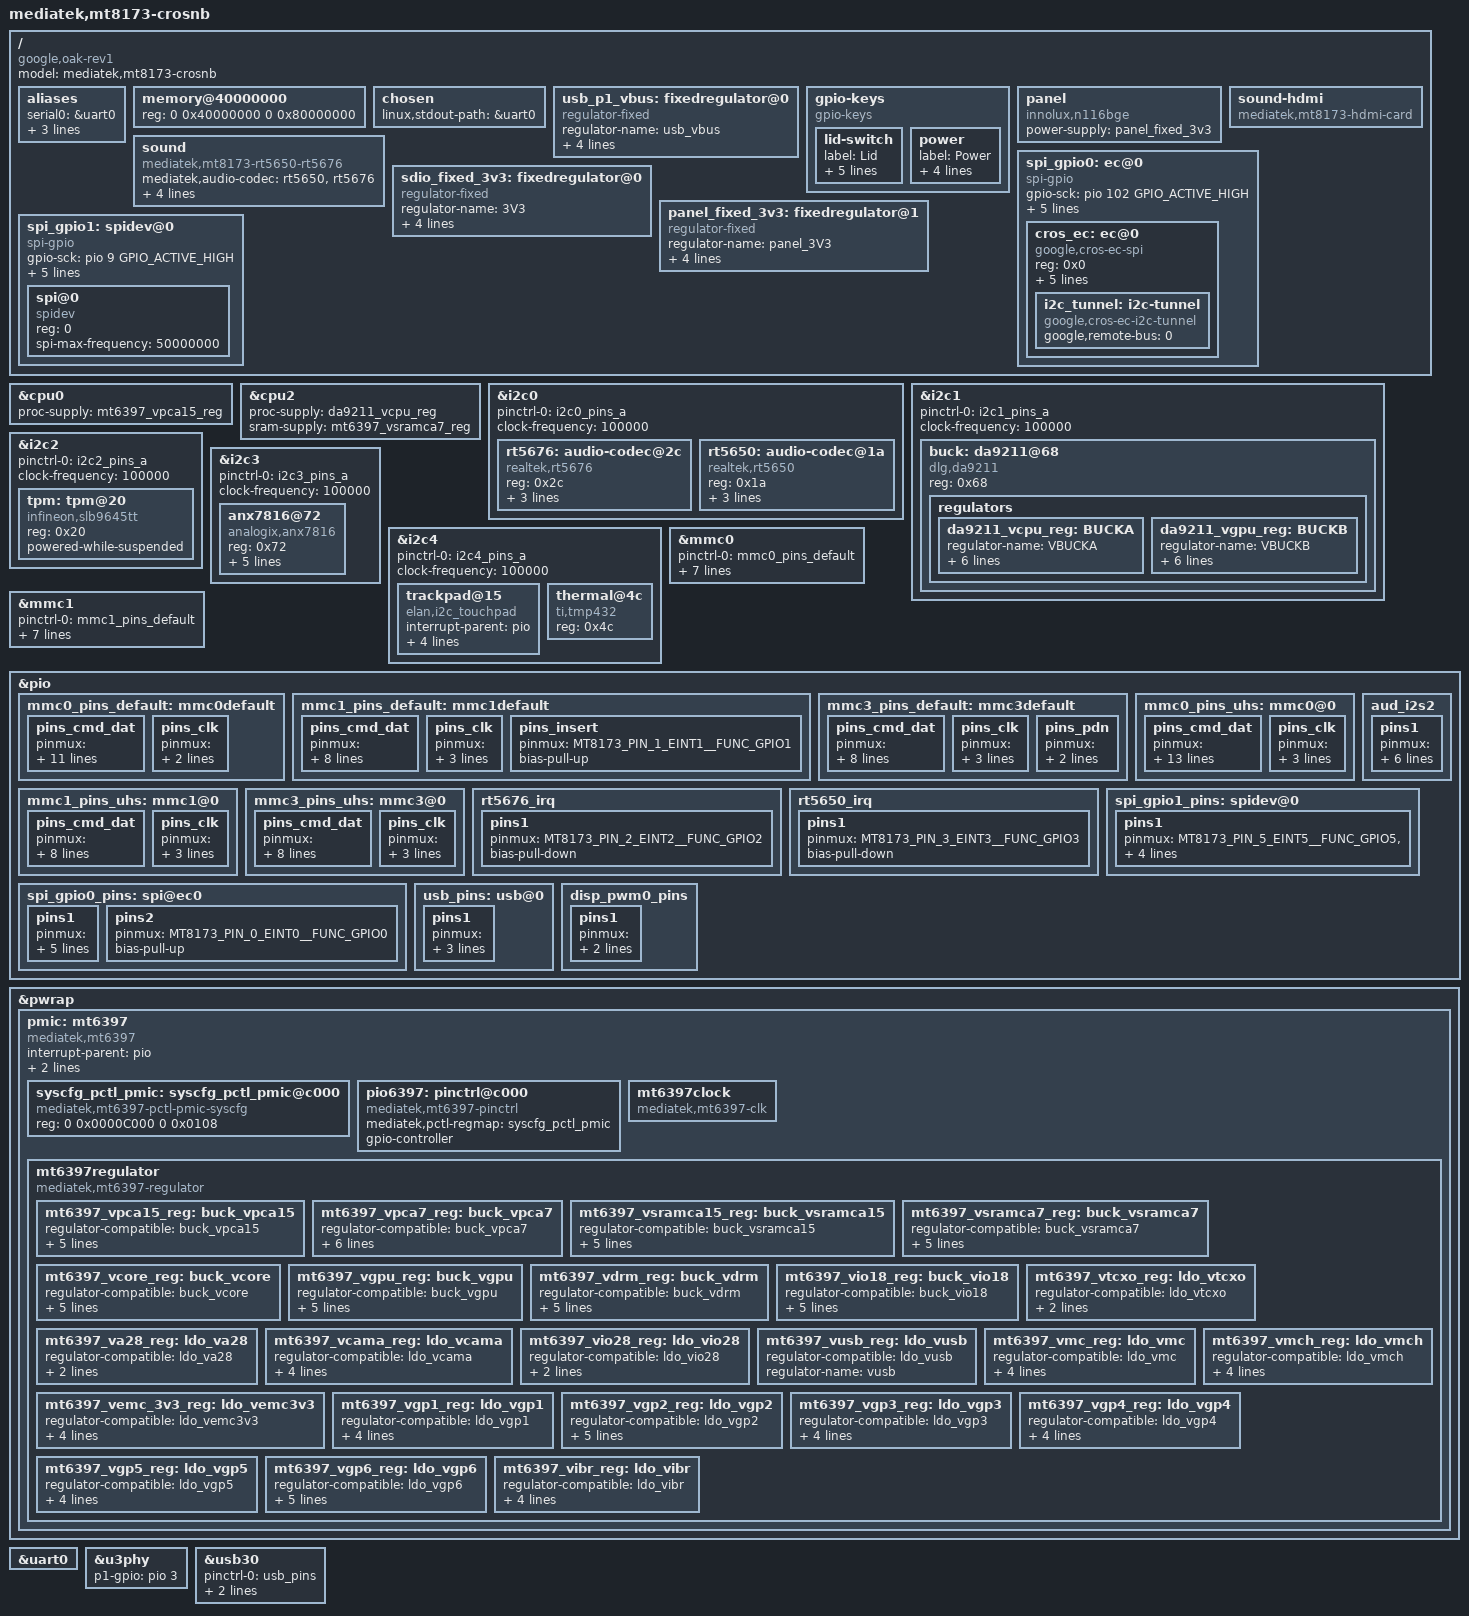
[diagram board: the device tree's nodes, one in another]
/*
 * Copyright (c) 2014 MediaTek Inc.
 * Author: Eddie Huang <eddie.huang@mediatek.com>
 *
 * This program is free software; you can redistribute it and/or modify
 * it under the terms of the GNU General Public License version 2 as
 * published by the Free Software Foundation.
 *
 * This program is distributed in the hope that it will be useful,
 * but WITHOUT ANY WARRANTY; without even the implied warranty of
 * MERCHANTABILITY or FITNESS FOR A PARTICULAR PURPOSE.  See the
 * GNU General Public License for more details.
 */

/dts-v1/;
#include <dt-bindings/input/input.h>
#include <dt-bindings/gpio/gpio.h>
#include "mt8173.dtsi"
#include "mt8173-pinfunc.h"

/ {
	model = "mediatek,mt8173-crosnb";
	compatible = "google,oak-rev1","google,oak","mediatek,mt8173";

	aliases {
		serial0 = &uart0;
		serial1 = &uart1;
		serial2 = &uart2;
		serial3 = &uart3;
	};

	memory@40000000 {
		device_type = "memory";
		reg = <0 0x40000000 0 0x80000000>;
	};

	chosen {
		linux,stdout-path = &uart0;
	};

	usb_p1_vbus: fixedregulator@0 {
		compatible = "regulator-fixed";
		regulator-name = "usb_vbus";
		regulator-min-microvolt = <5000000>;
		regulator-max-microvolt = <5000000>;
		gpio = <&pio 130 GPIO_ACTIVE_HIGH>;
		enable-active-high;
	};

	gpio-keys {
		compatible = "gpio-keys";
		lid-switch {
			label = "Lid";
			gpios = <&pio 12 GPIO_ACTIVE_LOW>;
			linux,input-type = <5>; /* EV_SW */
			linux,code = <0>; /* SW_LID */
			debounce-interval = <1>;
			gpio-key,wakeup;
		};
		power {
			label = "Power";
			gpios = <&pio 14 GPIO_ACTIVE_HIGH>;
			linux,code = <KEY_POWER>;
			debounce-interval = <1>;
			gpio-key,wakeup;
		};
	};

	panel: panel {
		compatible = "innolux,n116bge";
		power-supply =  <&panel_fixed_3v3>;
	};

	sound-hdmi {
		compatible = "mediatek,mt8173-hdmi-card";
	};

	sound {
		compatible = "mediatek,mt8173-rt5650-rt5676";
		mediatek,audio-codec = <&rt5650 &rt5676>;
		rt5650-clk-en-gpios = <&pio 16 GPIO_ACTIVE_HIGH>;
		rt5676-clk-en-gpios = <&pio 17 GPIO_ACTIVE_HIGH>;
		reg-vgp1-supply = <&mt6397_vgp1_reg>;
		pinctrl-names = "default";
		pinctrl-0 = <&aud_i2s2>;
		status = "okay";
	};

	spi_gpio0: ec@0 {
		compatible = "spi-gpio";
		#address-cells = <0x1>;
		#size-cells = <0>;
		gpio-sck = <&pio 102 GPIO_ACTIVE_HIGH>;
		gpio-miso = <&pio 103 GPIO_ACTIVE_HIGH>;
		gpio-mosi = <&pio 104 GPIO_ACTIVE_HIGH>;
		cs-gpios = <&pio 105 GPIO_ACTIVE_HIGH>;
		num-chipselects = <1>;
		pinctrl-names = "default";
		pinctrl-0 = <&spi_gpio0_pins>;
		status = "okay";
		/* clients */
		cros_ec: ec@0 {
			compatible = "google,cros-ec-spi";
			reg = <0x0>;
			spi-max-frequency = <18000000>;
			interrupt-parent = <&pio>;
			interrupts = <0 IRQ_TYPE_LEVEL_LOW>;
			google,cros-ec-spi-msg-delay = <500>;
			google,cros-ec-spi-pre-delay = <500>;

			i2c_tunnel: i2c-tunnel {
				compatible = "google,cros-ec-i2c-tunnel";
				google,remote-bus = <0>;
				#address-cells = <1>;
				#size-cells = <0>;
			};
		};
	};

	sdio_fixed_3v3: fixedregulator@0 {
		compatible = "regulator-fixed";
		regulator-name = "3V3";
		regulator-min-microvolt = <3300000>;
		regulator-max-microvolt = <3300000>;
		gpio = <&pio 100 0>;
		enable-active-high;
	};

	panel_fixed_3v3: fixedregulator@1 {
		compatible = "regulator-fixed";
		regulator-name = "panel_3V3";
		regulator-min-microvolt = <3300000>;
		regulator-max-microvolt = <3300000>;
		gpio = <&pio 41 0>;
		enable-active-high;
	};

	spi_gpio1: spidev@0 {
		compatible = "spi-gpio";
		#address-cells = <0x1>;
		#size-cells = <0>;

		gpio-sck = <&pio 9 GPIO_ACTIVE_HIGH>;
		gpio-miso = <&pio 5 GPIO_ACTIVE_HIGH>;
		gpio-mosi = <&pio 8 GPIO_ACTIVE_HIGH>;
		num-chipselects = <1>;
		cs-gpios = <&pio 6 GPIO_ACTIVE_LOW>;

		pinctrl-names = "default";
		pinctrl-0 = <&spi_gpio1_pins>;
		status = "okay";

		spi@0{
			compatible = "spidev";
			reg = <0>;
			spi-max-frequency = <50000000>;
		};
	};
};

&cpu0 {
	proc-supply = <&mt6397_vpca15_reg>;
};

&cpu2 {
	proc-supply = <&da9211_vcpu_reg>;
	sram-supply = <&mt6397_vsramca7_reg>;
};

&i2c0 {
	pinctrl-names = "default";
	pinctrl-0 = <&i2c0_pins_a>;
	status = "okay";
	clock-frequency = <100000>;
	#address-cells = <1>;
	#size-cells = <0>;
	rt5676: audio-codec@2c {
		compatible = "realtek,rt5676";
		reg = <0x2c>;
		interrupt-parent = <&pio>;
		interrupts = <2 IRQ_TYPE_EDGE_BOTH>;
		pinctrl-names = "default";
		pinctrl-0 = <&rt5676_irq>;
		status = "okay";
	};

	rt5650: audio-codec@1a {
		compatible = "realtek,rt5650";
		reg = <0x1a>;
		interrupt-parent = <&pio>;
		interrupts = <3 IRQ_TYPE_EDGE_BOTH>;
		pinctrl-names = "default";
		pinctrl-0 = <&rt5650_irq>;
		status = "okay";
	};
};

&i2c1 {
	pinctrl-names = "default";
	pinctrl-0 = <&i2c1_pins_a>;
	status = "okay";
	clock-frequency = <100000>;
	#address-cells = <1>;
	#size-cells = <0>;
	buck: da9211@68 {
		compatible = "dlg,da9211";
		reg = <0x68>;
		regulators {
			da9211_vcpu_reg: BUCKA {
				regulator-name = "VBUCKA";
				regulator-min-microvolt = < 700000>;
				regulator-max-microvolt = <1310000>;
				regulator-min-microamp	= <2000000>;
				regulator-max-microamp	= <4400000>;
				regulator-ramp-delay = <10000>;
				regulator-always-on;
			};
			da9211_vgpu_reg: BUCKB {
				regulator-name = "VBUCKB";
				regulator-min-microvolt = < 700000>;
				regulator-max-microvolt = <1310000>;
				regulator-min-microamp	= <2000000>;
				regulator-max-microamp	= <3000000>;
				regulator-ramp-delay = <10000>;
				regulator-always-on;
			};
		};
	};
};

&i2c2 {
	pinctrl-names = "default";
	pinctrl-0 = <&i2c2_pins_a>;
	status = "okay";
	clock-frequency = <100000>;
	#address-cells = <0x1>;
	#size-cells = <0>;
	tpm: tpm@20 {
		compatible = "infineon,slb9645tt";
		reg = <0x20>;
		powered-while-suspended;
	};
};

&i2c3 {
	pinctrl-names = "default";
	pinctrl-0 = <&i2c3_pins_a>;
	status = "okay";
	clock-frequency = <100000>;
	#address-cells = <0x1>;
	#size-cells = <0>;

	anx7816@72 {
		compatible = "analogix,anx7816";
		status = "ok";
		reg = <0x72>;
		analogix,p-dwn-gpio = <&pio 33 0x0>;
		analogix,reset-gpio = <&pio 98 0x0>;
		analogix,v10-ctrl-gpio = <&pio 35 0x0>;
		analogix,external-ldo-control = <1>;
		analogix,i2c-pull-up = <1>;
	};
};

&i2c4 {
	pinctrl-names = "default";
	pinctrl-0 = <&i2c4_pins_a>;
	status = "okay";
	clock-frequency = <100000>;
	#address-cells = <0x1>;
	#size-cells = <0>;
	trackpad@15 {
		compatible = "elan,i2c_touchpad";
		interrupt-parent = <&pio>;
		interrupts = <124 IRQ_TYPE_LEVEL_LOW>;
		reg = <0x15>;
		vcc-supply = <&mt6397_vgp6_reg>;
		wakeup-source;
	};
	thermal@4c {
		compatible = "ti,tmp432";
		reg = <0x4c>;
	};
};

&mmc0 {
	pinctrl-names = "default", "state_uhs";
	pinctrl-0 = <&mmc0_pins_default>;
	pinctrl-1 = <&mmc0_pins_uhs>;
	status = "okay";
	bus-width = <8>;
	max-frequency = <25000000>;
	cap-mmc-highspeed;
	vmmc-supply = <&mt6397_vemc_3v3_reg>;
	vqmmc-supply = <&mt6397_vio18_reg>;
	non-removable;
};

&mmc1 {
	pinctrl-names = "default", "state_uhs";
	pinctrl-0 = <&mmc1_pins_default>;
	pinctrl-1 = <&mmc1_pins_uhs>;
	status = "okay";
	bus-width = <8>;
	max-frequency = <25000000>;
	cap-sd-highspeed;
	sd-uhs-sdr25;
	vmmc-supply = <&mt6397_vmch_reg>;
	vqmmc-supply = <&mt6397_vmc_reg>;
};

&pio {
	mmc0_pins_default: mmc0default {
		pins_cmd_dat {
			pinmux = <MT8173_PIN_57_MSDC0_DAT0__FUNC_MSDC0_DAT0>,
				 <MT8173_PIN_58_MSDC0_DAT1__FUNC_MSDC0_DAT1>,
				 <MT8173_PIN_59_MSDC0_DAT2__FUNC_MSDC0_DAT2>,
				 <MT8173_PIN_60_MSDC0_DAT3__FUNC_MSDC0_DAT3>,
				 <MT8173_PIN_61_MSDC0_DAT4__FUNC_MSDC0_DAT4>,
				 <MT8173_PIN_62_MSDC0_DAT5__FUNC_MSDC0_DAT5>,
				 <MT8173_PIN_63_MSDC0_DAT6__FUNC_MSDC0_DAT6>,
				 <MT8173_PIN_64_MSDC0_DAT7__FUNC_MSDC0_DAT7>,
				 <MT8173_PIN_66_MSDC0_CMD__FUNC_MSDC0_CMD>,
				 <MT8173_PIN_68_MSDC0_RST___FUNC_MSDC0_RSTB>;
				bias-pull-up;
		};
		pins_clk {
			pinmux =  <MT8173_PIN_65_MSDC0_CLK__FUNC_MSDC0_CLK>;
				bias-pull-down;
		};
	};

	mmc1_pins_default: mmc1default {
		pins_cmd_dat {
			pinmux = <MT8173_PIN_73_MSDC1_DAT0__FUNC_MSDC1_DAT0>,
				 <MT8173_PIN_74_MSDC1_DAT1__FUNC_MSDC1_DAT1>,
				 <MT8173_PIN_75_MSDC1_DAT2__FUNC_MSDC1_DAT2>,
				 <MT8173_PIN_76_MSDC1_DAT3__FUNC_MSDC1_DAT3>,
				 <MT8173_PIN_78_MSDC1_CMD__FUNC_MSDC1_CMD>;
			input-enable;
			drive-strength = <MTK_DRIVE_4mA>;
			bias-pull-up = <MTK_PUPD_SET_R1R0_10>;
		};

		pins_clk {
			pinmux = <MT8173_PIN_77_MSDC1_CLK__FUNC_MSDC1_CLK>;
			bias-pull-down;
			drive-strength = <MTK_DRIVE_4mA>;
		};

		pins_insert {
			pinmux = <MT8173_PIN_1_EINT1__FUNC_GPIO1>;
			bias-pull-up;
		};
	};

	mmc3_pins_default: mmc3default {
		pins_cmd_dat {
			pinmux = <MT8173_PIN_22_MSDC3_DAT0__FUNC_MSDC3_DAT0>,
				 <MT8173_PIN_23_MSDC3_DAT1__FUNC_MSDC3_DAT1>,
				 <MT8173_PIN_24_MSDC3_DAT2__FUNC_MSDC3_DAT2>,
				 <MT8173_PIN_25_MSDC3_DAT3__FUNC_MSDC3_DAT3>,
				 <MT8173_PIN_27_MSDC3_CMD__FUNC_MSDC3_CMD>;
			input-enable;
			drive-strength = <MTK_DRIVE_4mA>;
			bias-pull-up = <MTK_PUPD_SET_R1R0_10>;
		};

		pins_clk {
			pinmux = <MT8173_PIN_26_MSDC3_CLK__FUNC_MSDC3_CLK>;
			bias-pull-down;
			drive-strength = <MTK_DRIVE_4mA>;
		};

		pins_pdn {
			pinmux = <MT8173_PIN_100_MSDC2_DAT0__FUNC_GPIO100>;
			output-high;
		};
	};

	mmc0_pins_uhs: mmc0@0{
		pins_cmd_dat {
			pinmux = <MT8173_PIN_57_MSDC0_DAT0__FUNC_MSDC0_DAT0>,
				 <MT8173_PIN_58_MSDC0_DAT1__FUNC_MSDC0_DAT1>,
				 <MT8173_PIN_59_MSDC0_DAT2__FUNC_MSDC0_DAT2>,
				 <MT8173_PIN_60_MSDC0_DAT3__FUNC_MSDC0_DAT3>,
				 <MT8173_PIN_61_MSDC0_DAT4__FUNC_MSDC0_DAT4>,
				 <MT8173_PIN_62_MSDC0_DAT5__FUNC_MSDC0_DAT5>,
				 <MT8173_PIN_63_MSDC0_DAT6__FUNC_MSDC0_DAT6>,
				 <MT8173_PIN_64_MSDC0_DAT7__FUNC_MSDC0_DAT7>,
				 <MT8173_PIN_68_MSDC0_RST___FUNC_MSDC0_RSTB>,
				 <MT8173_PIN_66_MSDC0_CMD__FUNC_MSDC0_CMD>;
			input-enable;
			drive-strength = <MTK_DRIVE_2mA>;
			bias-pull-up = <MTK_PUPD_SET_R1R0_01>;
		};

		pins_clk {
			pinmux = <MT8173_PIN_65_MSDC0_CLK__FUNC_MSDC0_CLK>;
			drive-strength = <MTK_DRIVE_2mA>;
			bias-pull-down = <MTK_PUPD_SET_R1R0_01>;
		};
	};

	mmc1_pins_uhs: mmc1@0 {
		pins_cmd_dat {
			pinmux = <MT8173_PIN_73_MSDC1_DAT0__FUNC_MSDC1_DAT0>,
				 <MT8173_PIN_74_MSDC1_DAT1__FUNC_MSDC1_DAT1>,
				 <MT8173_PIN_75_MSDC1_DAT2__FUNC_MSDC1_DAT2>,
				 <MT8173_PIN_76_MSDC1_DAT3__FUNC_MSDC1_DAT3>,
				 <MT8173_PIN_78_MSDC1_CMD__FUNC_MSDC1_CMD>;
			input-enable;
			drive-strength = <MTK_DRIVE_4mA>;
			bias-pull-up = <MTK_PUPD_SET_R1R0_10>;
		};

		pins_clk {
			pinmux = <MT8173_PIN_77_MSDC1_CLK__FUNC_MSDC1_CLK>;
			drive-strength = <MTK_DRIVE_4mA>;
			bias-pull-down = <MTK_PUPD_SET_R1R0_10>;
		};
	};

	mmc3_pins_uhs: mmc3@0 {
		pins_cmd_dat {
			pinmux = <MT8173_PIN_22_MSDC3_DAT0__FUNC_MSDC3_DAT0>,
				 <MT8173_PIN_23_MSDC3_DAT1__FUNC_MSDC3_DAT1>,
				 <MT8173_PIN_24_MSDC3_DAT2__FUNC_MSDC3_DAT2>,
				 <MT8173_PIN_25_MSDC3_DAT3__FUNC_MSDC3_DAT3>,
				 <MT8173_PIN_27_MSDC3_CMD__FUNC_MSDC3_CMD>;
			input-enable;
			drive-strength = <MTK_DRIVE_4mA>;
			bias-pull-up = <MTK_PUPD_SET_R1R0_10>;
		};

		pins_clk {
			pinmux = <MT8173_PIN_26_MSDC3_CLK__FUNC_MSDC3_CLK>;
			drive-strength = <MTK_DRIVE_4mA>;
			bias-pull-down = <MTK_PUPD_SET_R1R0_10>;
		};
	};

	aud_i2s2: aud_i2s2 {
		pins1 {
			pinmux = <MT8173_PIN_128_I2S0_LRCK__FUNC_I2S1_WS>,
					<MT8173_PIN_129_I2S0_BCK__FUNC_I2S1_BCK>,
					<MT8173_PIN_130_I2S0_MCK__FUNC_I2S1_MCK>,
					<MT8173_PIN_131_I2S0_DATA0__FUNC_I2S1_DO_1>,
					<MT8173_PIN_132_I2S0_DATA1__FUNC_I2S2_DI_2>;
			bias-pull-down;
		};
	};
	rt5676_irq: rt5676_irq {
		pins1 {
			pinmux = <MT8173_PIN_2_EINT2__FUNC_GPIO2>;
			bias-pull-down;
		};
	};

	rt5650_irq: rt5650_irq {
		pins1 {
			pinmux = <MT8173_PIN_3_EINT3__FUNC_GPIO3>;
			bias-pull-down;
		};
	};

	spi_gpio0_pins: spi@ec0 {
		pins1 {
			pinmux = <MT8173_PIN_102_MSDC2_DAT2__FUNC_GPIO102>,
				 <MT8173_PIN_103_MSDC2_DAT3__FUNC_GPIO103>,
				 <MT8173_PIN_104_MSDC2_CLK__FUNC_GPIO104>,
				 <MT8173_PIN_105_MSDC2_CMD__FUNC_GPIO105>;
			bias-disable;
		};

		pins2 {
			pinmux = <MT8173_PIN_0_EINT0__FUNC_GPIO0>;
			bias-pull-up;
		};
	};

	spi_gpio1_pins: spidev@0 {
		pins1 {
			pinmux = <MT8173_PIN_5_EINT5__FUNC_GPIO5>,
				 <MT8173_PIN_6_EINT6__FUNC_GPIO6>,
				 <MT8173_PIN_8_EINT8__FUNC_GPIO8>,
				 <MT8173_PIN_9_EINT9__FUNC_GPIO9>;
			bias-disable;
		};
	};

	usb_pins: usb@0 {
		pins1 {
			pinmux = <MT8173_PIN_101_MSDC2_DAT1__FUNC_GPIO101>;
			output-high;
			bias-disable;
		};
	};

	disp_pwm0_pins: disp_pwm0_pins{
		pins1 {
			pinmux = <MT8173_PIN_87_DISP_PWM0__FUNC_DISP_PWM0>;
			bias-pull-up;
		};
	};
};

&pwrap {
	pmic: mt6397 {
		compatible = "mediatek,mt6397";
		#address-cells = <1>;
		#size-cells = <1>;
		interrupt-parent = <&pio>;
		interrupts = <11 IRQ_TYPE_LEVEL_HIGH>;
		interrupt-controller;
		#interrupt-cells = <2>;

		syscfg_pctl_pmic: syscfg_pctl_pmic@c000 {
			compatible = "mediatek,mt6397-pctl-pmic-syscfg",
				     "syscon";
			reg = <0 0x0000C000 0 0x0108>;
		};

		pio6397: pinctrl@c000 {
			compatible = "mediatek,mt6397-pinctrl";
			mediatek,pctl-regmap = <&syscfg_pctl_pmic>;
			gpio-controller;
		};

		mt6397clock: mt6397clock {
			compatible = "mediatek,mt6397-clk";
			#clock-cells = <1>;
		};

		mt6397regulator: mt6397regulator {
			compatible = "mediatek,mt6397-regulator";

			mt6397_vpca15_reg: buck_vpca15 {
				regulator-compatible = "buck_vpca15";
				regulator-name = "vpca15";
				regulator-min-microvolt = < 700000>;
				regulator-max-microvolt = <1350000>;
				regulator-ramp-delay = <12500>;
				regulator-always-on;
			};

			mt6397_vpca7_reg: buck_vpca7 {
				regulator-compatible = "buck_vpca7";
				regulator-name = "vpca7";
				regulator-min-microvolt = < 700000>;
				regulator-max-microvolt = <1350000>;
				regulator-ramp-delay = <12500>;
				regulator-enable-ramp-delay = <115>;
				regulator-always-on;
			};

			mt6397_vsramca15_reg: buck_vsramca15 {
				regulator-compatible = "buck_vsramca15";
				regulator-name = "vsramca15";
				regulator-min-microvolt = < 700000>;
				regulator-max-microvolt = <1350000>;
				regulator-ramp-delay = <12500>;
				regulator-always-on;
			};

			mt6397_vsramca7_reg: buck_vsramca7 {
				regulator-compatible = "buck_vsramca7";
				regulator-name = "vsramca7";
				regulator-min-microvolt = < 700000>;
				regulator-max-microvolt = <1350000>;
				regulator-ramp-delay = <12500>;
				regulator-always-on;
			};

			mt6397_vcore_reg: buck_vcore {
				regulator-compatible = "buck_vcore";
				regulator-name = "vcore";
				regulator-min-microvolt = < 700000>;
				regulator-max-microvolt = <1350000>;
				regulator-ramp-delay = <12500>;
				regulator-always-on;
			};

			mt6397_vgpu_reg: buck_vgpu {
				regulator-compatible = "buck_vgpu";
				regulator-name = "vgpu";
				regulator-min-microvolt = < 700000>;
				regulator-max-microvolt = <1350000>;
				regulator-ramp-delay = <12500>;
				regulator-enable-ramp-delay = <115>;
			};

			mt6397_vdrm_reg: buck_vdrm {
				regulator-compatible = "buck_vdrm";
				regulator-name = "vdrm";
				regulator-min-microvolt = <1200000>;
				regulator-max-microvolt = <1400000>;
				regulator-ramp-delay = <12500>;
				regulator-always-on;
			};

			mt6397_vio18_reg: buck_vio18 {
				regulator-compatible = "buck_vio18";
				regulator-name = "vio18";
				regulator-min-microvolt = <1620000>;
				regulator-max-microvolt = <1980000>;
				regulator-ramp-delay = <12500>;
				regulator-always-on;
			};

			mt6397_vtcxo_reg: ldo_vtcxo {
				regulator-compatible = "ldo_vtcxo";
				regulator-name = "vtcxo";
				regulator-always-on;
			};

			mt6397_va28_reg: ldo_va28 {
				regulator-compatible = "ldo_va28";
				regulator-name = "va28";
				regulator-always-on;
			};

			mt6397_vcama_reg: ldo_vcama {
				regulator-compatible = "ldo_vcama";
				regulator-name = "vcama";
				regulator-min-microvolt = <1500000>;
				regulator-max-microvolt = <2800000>;
				regulator-enable-ramp-delay = <218>;
			};

			mt6397_vio28_reg: ldo_vio28 {
				regulator-compatible = "ldo_vio28";
				regulator-name = "vio28";
				regulator-always-on;
			};

			mt6397_vusb_reg: ldo_vusb {
				regulator-compatible = "ldo_vusb";
				regulator-name = "vusb";
			};

			mt6397_vmc_reg: ldo_vmc {
				regulator-compatible = "ldo_vmc";
				regulator-name = "vmc";
				regulator-min-microvolt = <1800000>;
				regulator-max-microvolt = <3300000>;
				regulator-enable-ramp-delay = <218>;
			};

			mt6397_vmch_reg: ldo_vmch {
				regulator-compatible = "ldo_vmch";
				regulator-name = "vmch";
				regulator-min-microvolt = <3000000>;
				regulator-max-microvolt = <3300000>;
				regulator-enable-ramp-delay = <218>;
			};

			mt6397_vemc_3v3_reg: ldo_vemc3v3 {
				regulator-compatible = "ldo_vemc3v3";
				regulator-name = "vemc_3v3";
				regulator-min-microvolt = <3000000>;
				regulator-max-microvolt = <3300000>;
				regulator-enable-ramp-delay = <218>;
			};

			mt6397_vgp1_reg: ldo_vgp1 {
				regulator-compatible = "ldo_vgp1";
				regulator-name = "vcamd";
				regulator-min-microvolt = <1220000>;
				regulator-max-microvolt = <3300000>;
				regulator-enable-ramp-delay = <240>;
			};

			mt6397_vgp2_reg: ldo_vgp2 {
				regulator-compatible = "ldo_vgp2";
				regulator-name = "vcamio";
				regulator-min-microvolt = <1800000>;
				regulator-max-microvolt = <1800000>;
				regulator-enable-ramp-delay = <218>;
				regulator-always-on;
			};

			mt6397_vgp3_reg: ldo_vgp3 {
				regulator-compatible = "ldo_vgp3";
				regulator-name = "vcamaf";
				regulator-min-microvolt = <1620000>;
				regulator-max-microvolt = <1980000>;
				regulator-enable-ramp-delay = <218>;
			};

			mt6397_vgp4_reg: ldo_vgp4 {
				regulator-compatible = "ldo_vgp4";
				regulator-name = "vgp4";
				regulator-min-microvolt = <1200000>;
				regulator-max-microvolt = <3300000>;
				regulator-enable-ramp-delay = <218>;
			};

			mt6397_vgp5_reg: ldo_vgp5 {
				regulator-compatible = "ldo_vgp5";
				regulator-name = "vgp5";
				regulator-min-microvolt = <1200000>;
				regulator-max-microvolt = <3000000>;
				regulator-enable-ramp-delay = <218>;
			};

			mt6397_vgp6_reg: ldo_vgp6 {
				regulator-compatible = "ldo_vgp6";
				regulator-name = "vgp6";
				regulator-min-microvolt = <3300000>;
				regulator-max-microvolt = <3300000>;
				regulator-enable-ramp-delay = <218>;
				regulator-always-on;
			};

			mt6397_vibr_reg: ldo_vibr {
				regulator-compatible = "ldo_vibr";
				regulator-name = "vibr";
				regulator-min-microvolt = <1300000>;
				regulator-max-microvolt = <3300000>;
				regulator-enable-ramp-delay = <218>;
			};
		};
	};
};

&uart0 {
	status = "okay";
};

/*in fact is a switch between micro(low to device) and type A(high to host)*/
&u3phy {
	p1-gpio = <&pio 3 GPIO_ACTIVE_HIGH>;
};

&usb30 {
	pinctrl-names = "default";
	pinctrl-0 = <&usb_pins>;
	vusb33-supply = <&mt6397_vusb_reg>;
	vbus-supply = <&usb_p1_vbus>;
};
